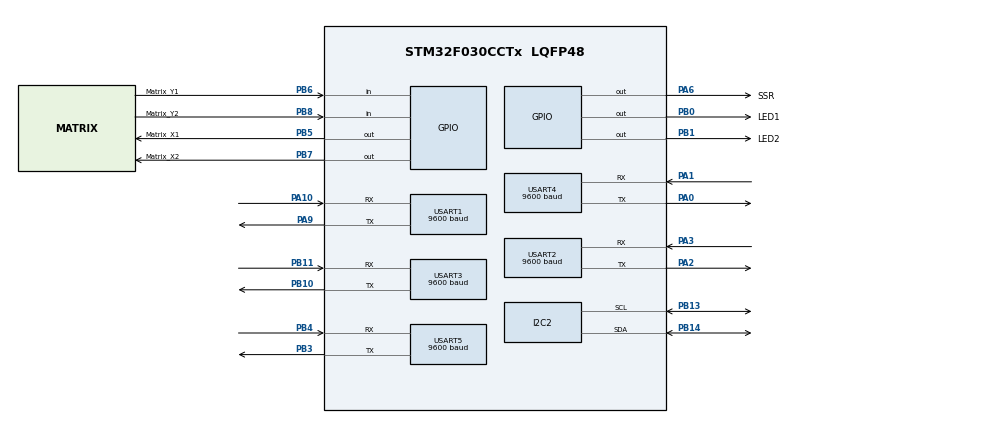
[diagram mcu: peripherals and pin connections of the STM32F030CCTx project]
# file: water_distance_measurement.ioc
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Mcu.Family=STM32F0
Mcu.Name=STM32F030CCTx
Mcu.Package=LQFP48
NVIC.FLASH_IRQn=true\:0\:0\:false\:false\:true\:true
NVIC.I2C2_IRQn=true\:0\:0\:false\:false\:true\:true
NVIC.USART1_IRQn=true\:0\:0\:false\:false\:true\:true
NVIC.USART2_IRQn=true\:0\:0\:false\:false\:true\:true
NVIC.USART3_6_IRQn=true\:0\:0\:false\:false\:true\:true
PA0.Mode=Asynchronous
PA0.Signal=USART4_TX
PA1.Mode=Asynchronous
PA1.Signal=USART4_RX
PA10.Mode=Asynchronous
PA10.Signal=USART1_RX
PA13.Mode=Serial_Wire
PA13.Signal=SYS_SWDIO
PA14.Mode=Serial_Wire
PA14.Signal=SYS_SWCLK
PA2.Mode=Asynchronous
PA2.Signal=USART2_TX
PA3.Mode=Asynchronous
PA3.Signal=USART2_RX
PA6.GPIO_Label=SSR
PA6.Signal=GPIO_Output
PA9.GPIO_FMA9=__NULL
PA9.Mode=Asynchronous
PA9.Signal=USART1_TX
PB0.GPIO_Label=LED1
PB0.PinState=GPIO_PIN_SET
PB0.Signal=GPIO_Output
PB1.GPIO_Label=LED2
PB1.PinState=GPIO_PIN_SET
PB1.Signal=GPIO_Output
PB10.Mode=Asynchronous
PB10.Signal=USART3_TX
PB11.Mode=Asynchronous
PB11.Signal=USART3_RX
PB13.GPIO_PuPdOD=GPIO_NOPULL
PB13.Mode=I2C
PB13.Signal=I2C2_SCL
PB14.GPIO_PuPdOD=GPIO_NOPULL
PB14.Mode=I2C
PB14.Signal=I2C2_SDA
PB3.Mode=Asynchronous
PB3.Signal=USART5_TX
PB4.Mode=Asynchronous
PB4.Signal=USART5_RX
PB5.GPIO_Label=Matrix_X1
PB5.Signal=GPIO_Output
PB6.GPIO_Label=Matrix_Y1
PB6.GPIO_PuPd=GPIO_PULLDOWN
PB6.Signal=GPIO_Input
PB7.GPIO_Label=Matrix_X2
PB7.Signal=GPIO_Output
PB8.GPIO_Label=Matrix_Y2
PB8.GPIO_PuPd=GPIO_PULLDOWN
PB8.Signal=GPIO_Input
ProjectManager.HeapSize=0x200
ProjectManager.StackSize=0x400
ProjectManager.TargetToolchain=Makefile
USART1.BaudRate=9600
USART1.VirtualMode-Asynchronous=VM_ASYNC
USART2.BaudRate=9600
USART2.VirtualMode-Asynchronous=VM_ASYNC
USART3.BaudRate=9600
USART3.VirtualMode-Asynchronous=VM_ASYNC
USART4.BaudRate=9600
USART4.VirtualMode-Asynchronous=VM_ASYNC
USART5.BaudRate=9600
USART5.VirtualMode-Asynchronous=VM_ASYNC
board=custom

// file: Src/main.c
/**
  ******************************************************************************
  * @file           : main.c
  * @brief          : Main program body
  ******************************************************************************
  ** This notice applies to any and all portions of this file
  * that are not between comment pairs USER CODE BEGIN and
  * USER CODE END. Other portions of this file, whether
  * inserted by the user or by software development tools
  * are owned by their respective copyright owners.
  *
  * COPYRIGHT(c) 2019 STMicroelectronics
  *
  * Redistribution and use in source and binary forms, with or without modification,
  * are permitted provided that the following conditions are met:
  *   1. Redistributions of source code must retain the above copyright notice,
  *      this list of conditions and the following disclaimer.
  *   2. Redistributions in binary form must reproduce the above copyright notice,
  *      this list of conditions and the following disclaimer in the documentation
  *      and/or other materials provided with the distribution.
  *   3. Neither the name of STMicroelectronics nor the names of its contributors
  *      may be used to endorse or promote products derived from this software
  *      without specific prior written permission.
  *
  * THIS SOFTWARE IS PROVIDED BY THE COPYRIGHT HOLDERS AND CONTRIBUTORS "AS IS"
  * AND ANY EXPRESS OR IMPLIED WARRANTIES, INCLUDING, BUT NOT LIMITED TO, THE
  * IMPLIED WARRANTIES OF MERCHANTABILITY AND FITNESS FOR A PARTICULAR PURPOSE ARE
  * DISCLAIMED. IN NO EVENT SHALL THE COPYRIGHT HOLDER OR CONTRIBUTORS BE LIABLE
  * FOR ANY DIRECT, INDIRECT, INCIDENTAL, SPECIAL, EXEMPLARY, OR CONSEQUENTIAL
  * DAMAGES (INCLUDING, BUT NOT LIMITED TO, PROCUREMENT OF SUBSTITUTE GOODS OR
  * SERVICES; LOSS OF USE, DATA, OR PROFITS; OR BUSINESS INTERRUPTION) HOWEVER
  * CAUSED AND ON ANY THEORY OF LIABILITY, WHETHER IN CONTRACT, STRICT LIABILITY,
  * OR TORT (INCLUDING NEGLIGENCE OR OTHERWISE) ARISING IN ANY WAY OUT OF THE USE
  * OF THIS SOFTWARE, EVEN IF ADVISED OF THE POSSIBILITY OF SUCH DAMAGE.
  *
  ******************************************************************************
  */
#include "main.h"
#include "stm32f0xx_hal.h"

/* USER CODE BEGIN Includes */

#include "../Drivers/STM32F0xx_HAL_Driver/Inc/stm32f0xx_hal_rcc.h"
#include "../Drivers/STM32F0xx_HAL_Driver/Inc/stm32f0xx_hal_cortex.h"
#include "../Drivers/STM32F0xx_HAL_Driver/Inc/stm32f0xx_hal_flash.h"
#include "../Inc/main.h"
#include "../Drivers/STM32F0xx_HAL_Driver/Inc/stm32f0xx_hal_tim.h"
#include "../Drivers/STM32F0xx_HAL_Driver/Inc/stm32f0xx_hal_pwr.h"

/* USER CODE END Includes */

I2C_HandleTypeDef hi2c2;

UART_HandleTypeDef huart1;
UART_HandleTypeDef huart2;
UART_HandleTypeDef huart3;
UART_HandleTypeDef huart4;
UART_HandleTypeDef huart5;

/* USER CODE BEGIN PV */
/* Private variables ---------------------------------------------------------*/

/* USER CODE END PV */

void SystemClock_Config(void);
static void MX_GPIO_Init(void);
static void MX_USART1_UART_Init(void);
static void MX_USART2_UART_Init(void);
static void MX_USART3_UART_Init(void);
static void MX_USART4_UART_Init(void);
static void MX_USART5_UART_Init(void);
static void MX_I2C2_Init(void);

/* USER CODE BEGIN PFP */
/* Private function prototypes -----------------------------------------------*/

/* USER CODE END PFP */

int main(void)
{

  /* MCU Configuration----------------------------------------------------------*/

  /* Reset of all peripherals, Initializes the Flash interface and the Systick. */
  HAL_Init();

  /* Configure the system clock */
  SystemClock_Config();

  /* Initialize all configured peripherals */
  MX_GPIO_Init();
  MX_USART1_UART_Init();
  MX_USART2_UART_Init();
  MX_USART3_UART_Init();
  MX_USART4_UART_Init();
  MX_USART5_UART_Init();
  MX_I2C2_Init();
  /* USER CODE BEGIN 2 */
  //HAL_TIM_Base_Start_IT(&htim6);
  monitoring_init();
  /* USER CODE END 2 */

  /* Infinite loop */
  /* USER CODE BEGIN WHILE */
  while (1)
  {
    monitoring_loop();

  /* USER CODE END WHILE */

  }

}

void SystemClock_Config(void)
{

  RCC_OscInitTypeDef RCC_OscInitStruct;
  RCC_ClkInitTypeDef RCC_ClkInitStruct;
  RCC_PeriphCLKInitTypeDef PeriphClkInit;

    /**Initializes the CPU, AHB and APB busses clocks
    */
  RCC_OscInitStruct.OscillatorType = RCC_OSCILLATORTYPE_HSI;
  RCC_OscInitStruct.HSIState = RCC_HSI_ON;
  RCC_OscInitStruct.HSICalibrationValue = 16;
  RCC_OscInitStruct.PLL.PLLState = RCC_PLL_NONE;
  if (HAL_RCC_OscConfig(&RCC_OscInitStruct) != HAL_OK)
  {
    _Error_Handler(__FILE__, __LINE__);
  }

    /**Initializes the CPU, AHB and APB busses clocks
    */
  RCC_ClkInitStruct.ClockType = RCC_CLOCKTYPE_HCLK|RCC_CLOCKTYPE_SYSCLK
                              |RCC_CLOCKTYPE_PCLK1;
  RCC_ClkInitStruct.SYSCLKSource = RCC_SYSCLKSOURCE_HSI;
  RCC_ClkInitStruct.AHBCLKDivider = RCC_SYSCLK_DIV1;
  RCC_ClkInitStruct.APB1CLKDivider = RCC_HCLK_DIV1;

  if (HAL_RCC_ClockConfig(&RCC_ClkInitStruct, FLASH_LATENCY_0) != HAL_OK)
  {
    _Error_Handler(__FILE__, __LINE__);
  }

  PeriphClkInit.PeriphClockSelection = RCC_PERIPHCLK_USART1;
  PeriphClkInit.Usart1ClockSelection = RCC_USART1CLKSOURCE_PCLK1;
  if (HAL_RCCEx_PeriphCLKConfig(&PeriphClkInit) != HAL_OK)
  {
    _Error_Handler(__FILE__, __LINE__);
  }

    /**Configure the Systick interrupt time
    */
  HAL_SYSTICK_Config(HAL_RCC_GetHCLKFreq()/1000);

    /**Configure the Systick
    */
  HAL_SYSTICK_CLKSourceConfig(SYSTICK_CLKSOURCE_HCLK);

  /* SysTick_IRQn interrupt configuration */
  HAL_NVIC_SetPriority(SysTick_IRQn, 0, 0);
}

/* I2C2 init function */
static void MX_I2C2_Init(void)
{

  hi2c2.Instance = I2C2;
  hi2c2.Init.Timing = 0x2000090E;
  hi2c2.Init.OwnAddress1 = 0;
  hi2c2.Init.AddressingMode = I2C_ADDRESSINGMODE_7BIT;
  hi2c2.Init.DualAddressMode = I2C_DUALADDRESS_DISABLE;
  hi2c2.Init.OwnAddress2 = 0;
  hi2c2.Init.OwnAddress2Masks = I2C_OA2_NOMASK;
  hi2c2.Init.GeneralCallMode = I2C_GENERALCALL_DISABLE;
  hi2c2.Init.NoStretchMode = I2C_NOSTRETCH_DISABLE;
  if (HAL_I2C_Init(&hi2c2) != HAL_OK)
  {
    _Error_Handler(__FILE__, __LINE__);
  }

    /**Configure Analogue filter
    */
  if (HAL_I2CEx_ConfigAnalogFilter(&hi2c2, I2C_ANALOGFILTER_ENABLE) != HAL_OK)
  {
    _Error_Handler(__FILE__, __LINE__);
  }

    /**Configure Digital filter
    */
  if (HAL_I2CEx_ConfigDigitalFilter(&hi2c2, 0) != HAL_OK)
  {
    _Error_Handler(__FILE__, __LINE__);
  }

}

/* USART1 init function */
static void MX_USART1_UART_Init(void)
{

  huart1.Instance = USART1;
  huart1.Init.BaudRate = 9600;
  huart1.Init.WordLength = UART_WORDLENGTH_8B;
  huart1.Init.StopBits = UART_STOPBITS_1;
  huart1.Init.Parity = UART_PARITY_NONE;
  huart1.Init.Mode = UART_MODE_TX_RX;
  huart1.Init.HwFlowCtl = UART_HWCONTROL_NONE;
  huart1.Init.OverSampling = UART_OVERSAMPLING_16;
  huart1.Init.OneBitSampling = UART_ONE_BIT_SAMPLE_DISABLE;
  huart1.AdvancedInit.AdvFeatureInit = UART_ADVFEATURE_NO_INIT;
  if (HAL_UART_Init(&huart1) != HAL_OK)
  {
    _Error_Handler(__FILE__, __LINE__);
  }

}

/* USART2 init function */
static void MX_USART2_UART_Init(void)
{

  huart2.Instance = USART2;
  huart2.Init.BaudRate = 9600;
  huart2.Init.WordLength = UART_WORDLENGTH_8B;
  huart2.Init.StopBits = UART_STOPBITS_1;
  huart2.Init.Parity = UART_PARITY_NONE;
  huart2.Init.Mode = UART_MODE_TX_RX;
  huart2.Init.HwFlowCtl = UART_HWCONTROL_NONE;
  huart2.Init.OverSampling = UART_OVERSAMPLING_16;
  huart2.Init.OneBitSampling = UART_ONE_BIT_SAMPLE_DISABLE;
  huart2.AdvancedInit.AdvFeatureInit = UART_ADVFEATURE_NO_INIT;
  if (HAL_UART_Init(&huart2) != HAL_OK)
  {
    _Error_Handler(__FILE__, __LINE__);
  }

}

/* USART3 init function */
static void MX_USART3_UART_Init(void)
{

  huart3.Instance = USART3;
  huart3.Init.BaudRate = 9600;
  huart3.Init.WordLength = UART_WORDLENGTH_8B;
  huart3.Init.StopBits = UART_STOPBITS_1;
  huart3.Init.Parity = UART_PARITY_NONE;
  huart3.Init.Mode = UART_MODE_TX_RX;
  huart3.Init.HwFlowCtl = UART_HWCONTROL_NONE;
  huart3.Init.OverSampling = UART_OVERSAMPLING_16;
  huart3.Init.OneBitSampling = UART_ONE_BIT_SAMPLE_DISABLE;
  huart3.AdvancedInit.AdvFeatureInit = UART_ADVFEATURE_NO_INIT;
  if (HAL_UART_Init(&huart3) != HAL_OK)
  {
    _Error_Handler(__FILE__, __LINE__);
  }

}

/* USART4 init function */
static void MX_USART4_UART_Init(void)
{

  huart4.Instance = USART4;
  huart4.Init.BaudRate = 9600;
  huart4.Init.WordLength = UART_WORDLENGTH_8B;
  huart4.Init.StopBits = UART_STOPBITS_1;
  huart4.Init.Parity = UART_PARITY_NONE;
  huart4.Init.Mode = UART_MODE_TX_RX;
  huart4.Init.HwFlowCtl = UART_HWCONTROL_NONE;
  huart4.Init.OverSampling = UART_OVERSAMPLING_16;
  huart4.Init.OneBitSampling = UART_ONE_BIT_SAMPLE_DISABLE;
  huart4.AdvancedInit.AdvFeatureInit = UART_ADVFEATURE_NO_INIT;
  if (HAL_UART_Init(&huart4) != HAL_OK)
  {
    _Error_Handler(__FILE__, __LINE__);
  }

}

/* USART5 init function */
static void MX_USART5_UART_Init(void)
{

  huart5.Instance = USART5;
  huart5.Init.BaudRate = 9600;
  huart5.Init.WordLength = UART_WORDLENGTH_8B;
  huart5.Init.StopBits = UART_STOPBITS_1;
  huart5.Init.Parity = UART_PARITY_NONE;
  huart5.Init.Mode = UART_MODE_TX_RX;
  huart5.Init.HwFlowCtl = UART_HWCONTROL_NONE;
  huart5.Init.OverSampling = UART_OVERSAMPLING_16;
  huart5.Init.OneBitSampling = UART_ONE_BIT_SAMPLE_DISABLE;
  huart5.AdvancedInit.AdvFeatureInit = UART_ADVFEATURE_NO_INIT;
  if (HAL_UART_Init(&huart5) != HAL_OK)
  {
    _Error_Handler(__FILE__, __LINE__);
  }

}

/** Configure pins as
        * Analog
        * Input
        * Output
        * EVENT_OUT
        * EXTI
        * Free pins are configured automatically as Analog (this feature is enabled through
        * the Code Generation settings)
*/
static void MX_GPIO_Init(void)
{

  GPIO_InitTypeDef GPIO_InitStruct;

  /* GPIO Ports Clock Enable */
  __HAL_RCC_GPIOC_CLK_ENABLE();
  __HAL_RCC_GPIOF_CLK_ENABLE();
  __HAL_RCC_GPIOA_CLK_ENABLE();
  __HAL_RCC_GPIOB_CLK_ENABLE();

  /*Configure GPIO pin Output Level */
  HAL_GPIO_WritePin(SSR_GPIO_Port, SSR_Pin, GPIO_PIN_RESET);

  /*Configure GPIO pin Output Level */
  HAL_GPIO_WritePin(GPIOB, LED1_Pin|LED2_Pin, GPIO_PIN_SET);

  /*Configure GPIO pin Output Level */
  HAL_GPIO_WritePin(GPIOB, Matrix_X1_Pin|Matrix_X2_Pin, GPIO_PIN_RESET);

  /*Configure GPIO pins : PC13 PC14 PC15 */
  GPIO_InitStruct.Pin = GPIO_PIN_13|GPIO_PIN_14|GPIO_PIN_15;
  GPIO_InitStruct.Mode = GPIO_MODE_ANALOG;
  GPIO_InitStruct.Pull = GPIO_NOPULL;
  HAL_GPIO_Init(GPIOC, &GPIO_InitStruct);

  /*Configure GPIO pins : PF0 PF1 */
  GPIO_InitStruct.Pin = GPIO_PIN_0|GPIO_PIN_1;
  GPIO_InitStruct.Mode = GPIO_MODE_ANALOG;
  GPIO_InitStruct.Pull = GPIO_NOPULL;
  HAL_GPIO_Init(GPIOF, &GPIO_InitStruct);

  /*Configure GPIO pins : PA4 PA5 PA7 PA8
                           PA11 PA12 PA15 */
  GPIO_InitStruct.Pin = GPIO_PIN_4|GPIO_PIN_5|GPIO_PIN_7|GPIO_PIN_8
                          |GPIO_PIN_11|GPIO_PIN_12|GPIO_PIN_15;
  GPIO_InitStruct.Mode = GPIO_MODE_ANALOG;
  GPIO_InitStruct.Pull = GPIO_NOPULL;
  HAL_GPIO_Init(GPIOA, &GPIO_InitStruct);

  /*Configure GPIO pin : SSR_Pin */
  GPIO_InitStruct.Pin = SSR_Pin;
  GPIO_InitStruct.Mode = GPIO_MODE_OUTPUT_PP;
  GPIO_InitStruct.Pull = GPIO_NOPULL;
  GPIO_InitStruct.Speed = GPIO_SPEED_FREQ_LOW;
  HAL_GPIO_Init(SSR_GPIO_Port, &GPIO_InitStruct);

  /*Configure GPIO pins : LED1_Pin LED2_Pin Matrix_X1_Pin Matrix_X2_Pin */
  GPIO_InitStruct.Pin = LED1_Pin|LED2_Pin|Matrix_X1_Pin|Matrix_X2_Pin;
  GPIO_InitStruct.Mode = GPIO_MODE_OUTPUT_PP;
  GPIO_InitStruct.Pull = GPIO_NOPULL;
  GPIO_InitStruct.Speed = GPIO_SPEED_FREQ_LOW;
  HAL_GPIO_Init(GPIOB, &GPIO_InitStruct);

  /*Configure GPIO pins : PB2 PB12 PB15 PB9 */
  GPIO_InitStruct.Pin = GPIO_PIN_2|GPIO_PIN_12|GPIO_PIN_15|GPIO_PIN_9;
  GPIO_InitStruct.Mode = GPIO_MODE_ANALOG;
  GPIO_InitStruct.Pull = GPIO_NOPULL;
  HAL_GPIO_Init(GPIOB, &GPIO_InitStruct);

  /*Configure GPIO pins : Matrix_Y1_Pin Matrix_Y2_Pin */
  GPIO_InitStruct.Pin = Matrix_Y1_Pin|Matrix_Y2_Pin;
  GPIO_InitStruct.Mode = GPIO_MODE_INPUT;
  GPIO_InitStruct.Pull = GPIO_PULLDOWN;
  HAL_GPIO_Init(GPIOB, &GPIO_InitStruct);

}

void _Error_Handler(char *file, int line)
{
  while(1)
  {
  }
}

/************************ (C) COPYRIGHT STMicroelectronics *****END OF FILE****/
